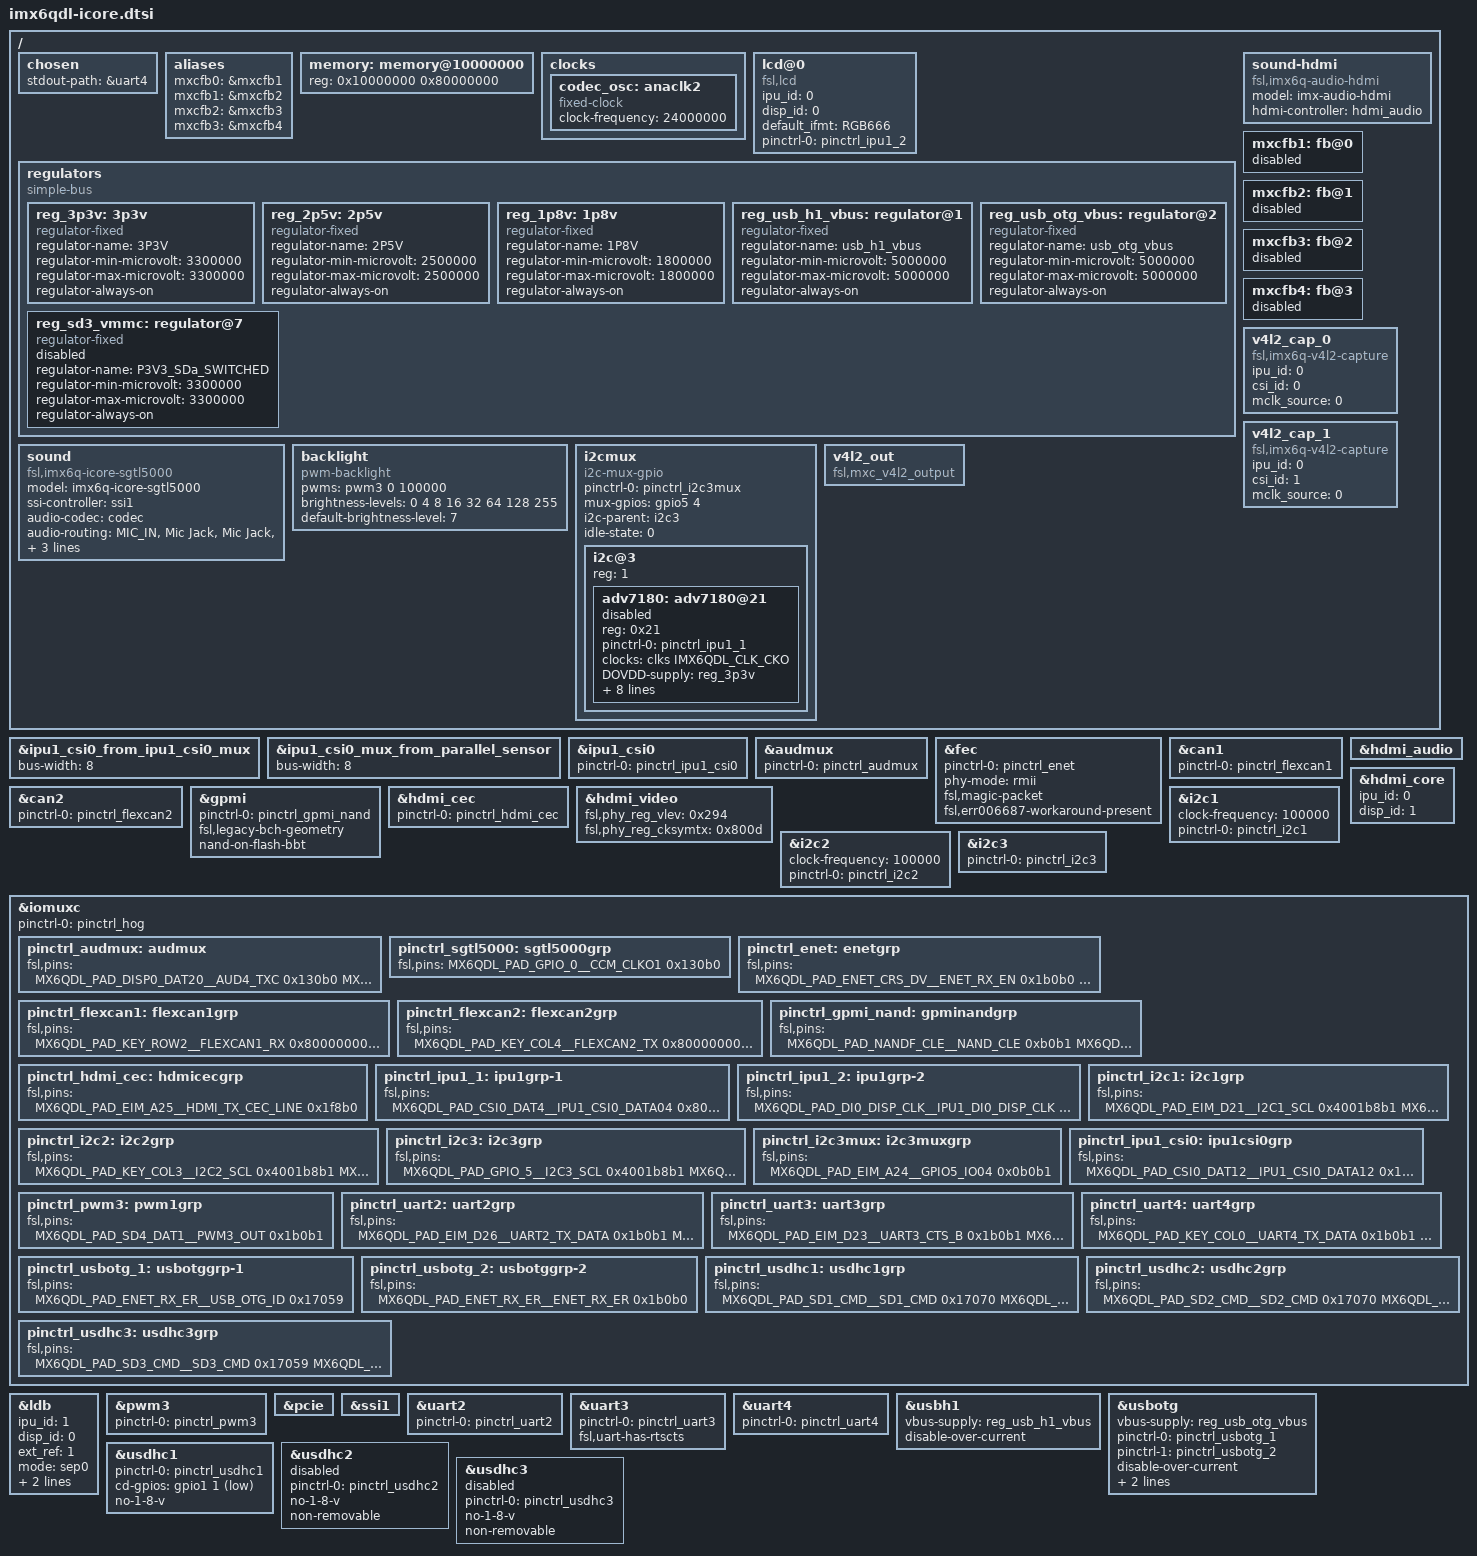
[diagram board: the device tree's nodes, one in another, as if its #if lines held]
// SPDX-License-Identifier: GPL-2.0+
//
// Copyright 2012 Freescale Semiconductor, Inc.
// Copyright 2011 Linaro Ltd.
// Based on imx6qdl-sabreauto.dtsi

#include <dt-bindings/gpio/gpio.h>
#include <dt-bindings/input/input.h>
#include "icore-imx6dl-pinfunc.h"
/ {
  
	chosen {
		stdout-path = &uart4;
	};

	aliases {
		mxcfb0 = &mxcfb1;
		mxcfb1 = &mxcfb2;
		mxcfb2 = &mxcfb3;
		mxcfb3 = &mxcfb4;
	};

	memory: memory@10000000 {
		reg = <0x10000000 0x80000000>;
	};

	clocks {
		codec_osc: anaclk2 {
			compatible = "fixed-clock";
			#clock-cells = <0>;
			clock-frequency = <24000000>;
		};
	};

	lcd@0 {
		compatible = "fsl,lcd";
		ipu_id = <0>;
		disp_id = <0>;
		default_ifmt = "RGB666";
		pinctrl-names = "default";
		pinctrl-0 = <&pinctrl_ipu1_2>;
		status = "okay";
	};

	regulators {
		compatible = "simple-bus";
		#address-cells = <1>;
		#size-cells = <0>;


		reg_3p3v: 3p3v {
			compatible = "regulator-fixed";
			regulator-name = "3P3V";
			regulator-min-microvolt = <3300000>;
			regulator-max-microvolt = <3300000>;
			regulator-always-on;
		};

		reg_2p5v: 2p5v {
			compatible = "regulator-fixed";
			regulator-name = "2P5V";
			regulator-min-microvolt = <2500000>;
			regulator-max-microvolt = <2500000>;
			regulator-always-on;
		};

		reg_1p8v: 1p8v {
			compatible = "regulator-fixed";
			regulator-name = "1P8V";
			regulator-min-microvolt = <1800000>;
			regulator-max-microvolt = <1800000>;
			regulator-always-on;
		};

		reg_usb_h1_vbus: regulator@1 {
			compatible = "regulator-fixed";
			regulator-name = "usb_h1_vbus";
			regulator-min-microvolt = <5000000>;
			regulator-max-microvolt = <5000000>;
			regulator-always-on;
		};

		reg_usb_otg_vbus: regulator@2 {
			compatible = "regulator-fixed";
			regulator-name = "usb_otg_vbus";
			regulator-min-microvolt = <5000000>;
			regulator-max-microvolt = <5000000>;
			regulator-always-on;
		};

		reg_sd3_vmmc: regulator@7 {
			compatible = "regulator-fixed";
			regulator-name = "P3V3_SDa_SWITCHED";
			regulator-min-microvolt = <3300000>;
			regulator-max-microvolt = <3300000>;
			regulator-always-on;
			status = "disabled";
		};

	};

	sound {
		compatible = "fsl,imx6q-icore-sgtl5000",
			     "fsl,imx-audio-sgtl5000";
		model = "imx6q-icore-sgtl5000";
		ssi-controller = <&ssi1>;
		audio-codec = <&codec>;
		audio-routing =
			"MIC_IN", "Mic Jack",
			"Mic Jack", "Mic Bias",
			"Headphone Jack", "HP_OUT";
		mux-int-port = <1>;
		mux-ext-port = <4>;
	};

	sound-hdmi {
		compatible = "fsl,imx6q-audio-hdmi",
			     "fsl,imx-audio-hdmi";
		model = "imx-audio-hdmi";
		hdmi-controller = <&hdmi_audio>;
	};

	mxcfb1: fb@0 {
		status = "disabled";
	};

	mxcfb2: fb@1 {
		status = "disabled";
	};

	mxcfb3: fb@2 {
		status = "disabled";
	};

	mxcfb4: fb@3 {
		status = "disabled";
	};



	backlight {
		compatible = "pwm-backlight";
		pwms = <&pwm3 0 100000>;
		brightness-levels = <0 4 8 16 32 64 128 255>;
		default-brightness-level = <7>;
		status = "okay";
	};

#ifdef TBT
	i2cmux { /* TBT */
		compatible = "i2c-mux-gpio";
		#address-cells = <1>;
		#size-cells = <0>;
		pinctrl-names = "default";
		pinctrl-0 = <&pinctrl_i2c3mux>;
		mux-gpios = <&gpio5 4 0>;
		i2c-parent = <&i2c3>;
		idle-state = <0>;

		i2c@3 {
			#address-cells = <1>;
			#size-cells = <0>;
			reg = <1>;

			adv7180: adv7180@21 {
				status = "disabled"
				compatible = "adv,adv7180";
				reg = <0x21>;
				pinctrl-names = "default";
				pinctrl-0 = <&pinctrl_ipu1_1>;
				clocks = <&clks IMX6QDL_CLK_CKO>;
				clock-names = "csi_mclk";
				DOVDD-supply = <&reg_3p3v>; /* 3.3v, enabled via 2.8 VGEN6 */
				AVDD-supply = <&reg_3p3v>;  /* 1.8v */
				DVDD-supply = <&reg_3p3v>;  /* 1.8v */
				PVDD-supply = <&reg_3p3v>;  /* 1.8v */
				pwn-gpios = <&max7310_b 2 0>;
				csi_id = <0>;
				mclk = <24000000>;
				mclk_source = <0>;
				cvbs = <1>;
			};

		};
	};
#endif
  
	v4l2_cap_0 {
		compatible = "fsl,imx6q-v4l2-capture";
		ipu_id = <0>;
		csi_id = <0>;
		mclk_source = <0>;
		status = "okay";
	};

	v4l2_cap_1 {
		compatible = "fsl,imx6q-v4l2-capture";
		ipu_id = <0>;
		csi_id = <1>;
		mclk_source = <0>;
		status = "okay";
	};

	v4l2_out {
		compatible = "fsl,mxc_v4l2_output";
		status = "okay";
	};
};

&ipu1_csi0_from_ipu1_csi0_mux {
	bus-width = <8>;
};

&ipu1_csi0_mux_from_parallel_sensor {
	/* Downstream driver doesn't use endpoints */
	/*
	remote-endpoint = <&adv7180_to_ipu1_csi0_mux>;
	 */
	bus-width = <8>;
};

&ipu1_csi0 {
	pinctrl-names = "default";
	pinctrl-0 = <&pinctrl_ipu1_csi0>;
};

&audmux {
	pinctrl-names = "default";
	pinctrl-0 = <&pinctrl_audmux>;
	status = "okay";
};

&fec {
	pinctrl-names = "default";
	pinctrl-0 = <&pinctrl_enet>;
	phy-mode = "rmii";
	fsl,magic-packet;
	fsl,err006687-workaround-present;
	status = "okay";
};

&can1 {
	pinctrl-names = "default";
	pinctrl-0 = <&pinctrl_flexcan1>;
	status = "okay"; 
};

&can2 {
	pinctrl-names = "default";
	pinctrl-0 = <&pinctrl_flexcan2>;
	status = "okay";
};

&gpmi {
	pinctrl-names = "default";
	pinctrl-0 = <&pinctrl_gpmi_nand>;
	status = "okay"; 
	fsl,legacy-bch-geometry;
	nand-on-flash-bbt;
};

&hdmi_audio {
	status = "okay";
};

&hdmi_cec {
	pinctrl-names = "default";
	pinctrl-0 = <&pinctrl_hdmi_cec>;
	status = "okay";
};

&hdmi_core {
	ipu_id = <0>;
	disp_id = <1>;
	status = "okay";
};

&hdmi_video {
	fsl,phy_reg_vlev = <0x294>;
	fsl,phy_reg_cksymtx = <0x800d>;
	status = "okay";
};

&i2c1 {
	status = "okay";
	clock-frequency = <100000>;
	pinctrl-names = "default";
	pinctrl-0 = <&pinctrl_i2c1>;

};

&i2c2 {
	clock-frequency = <100000>;
	pinctrl-names = "default";
	pinctrl-0 = <&pinctrl_i2c2>;
	status = "okay";
};

&i2c3 {
	pinctrl-names = "default";
	pinctrl-0 = <&pinctrl_i2c3>;
	status = "okay";
};

&iomuxc {
	pinctrl-names = "default";
	pinctrl-0 = <&pinctrl_hog>;

  pinctrl_audmux: audmux {
    fsl,pins = <
      MX6QDL_PAD_DISP0_DAT20__AUD4_TXC  0x130b0
      MX6QDL_PAD_DISP0_DAT21__AUD4_TXD 0x110b0
      MX6QDL_PAD_DISP0_DAT22__AUD4_TXFS  0x130b0
      MX6QDL_PAD_DISP0_DAT23__AUD4_RXD  0x130b0
      >;
  };

  /*pinctrl_hog: hoggrp {
    fsl,pins = <
      MX6QDL_PAD_SD3_CMD__GPIO7_IO02 0x1f059
    >;
  };*/
  
  pinctrl_sgtl5000: sgtl5000grp {
    fsl,pins = <
     MX6QDL_PAD_GPIO_0__CCM_CLKO1	0x130b0
     // MX6QDL_PAD_EIM_A25__GPIO5_IO02		0x1b0b0
    >;
  };

  pinctrl_enet: enetgrp {
    fsl,pins = <
      MX6QDL_PAD_ENET_CRS_DV__ENET_RX_EN 	0x1b0b0
      MX6QDL_PAD_ENET_TX_EN__ENET_TX_EN	0x1b0b0
      MX6QDL_PAD_ENET_RXD1__ENET_RX_DATA1	0x1b0b0
      MX6QDL_PAD_ENET_RXD0__ENET_RX_DATA0	0x1b0b0
      MX6QDL_PAD_ENET_TXD1__ENET_TX_DATA1	0x1b0b0
      MX6QDL_PAD_ENET_TXD0__ENET_TX_DATA0	0x1b0b0
            MX6QDL_PAD_ENET_MDC__ENET_MDC		0x1b0b0
      MX6QDL_PAD_ENET_MDIO__ENET_MDIO		0x1b0b0
      MX6QDL_PAD_ENET_REF_CLK__GPIO1_IO23	0x1b0b0
      MX6QDL_PAD_GPIO_17__GPIO7_IO12		0x1b0b0
      MX6QDL_PAD_EIM_BCLK__GPIO6_IO31		0x1b0b0 /* EDIMM 1.5 or 1.0 GPIO signal */
      MX6QDL_PAD_GPIO_16__ENET_REF_CLK_SION 0x4001b0a8
    >;
  };

  pinctrl_flexcan1: flexcan1grp {
    fsl,pins = <
      MX6QDL_PAD_KEY_ROW2__FLEXCAN1_RX 0x80000000
      MX6QDL_PAD_KEY_COL2__FLEXCAN1_TX 0x80000000
    >;
  };

  pinctrl_flexcan2: flexcan2grp {
    fsl,pins = <
      MX6QDL_PAD_KEY_COL4__FLEXCAN2_TX 0x80000000
      MX6QDL_PAD_KEY_ROW4__FLEXCAN2_RX 0x80000000
    >;
  };


  pinctrl_gpmi_nand: gpminandgrp {
    fsl,pins = <
      MX6QDL_PAD_NANDF_CLE__NAND_CLE		0xb0b1
      MX6QDL_PAD_NANDF_ALE__NAND_ALE		0xb0b1
      MX6QDL_PAD_NANDF_WP_B__NAND_WP_B	0xb0b1
      MX6QDL_PAD_NANDF_RB0__NAND_READY_B	0xb000
      MX6QDL_PAD_NANDF_CS0__NAND_CE0_B	0xb0b1
      MX6QDL_PAD_NANDF_CS1__NAND_CE1_B	0xb0b1
      MX6QDL_PAD_SD4_CMD__NAND_RE_B		0xb0b1
      MX6QDL_PAD_SD4_CLK__NAND_WE_B		0xb0b1
      MX6QDL_PAD_NANDF_D0__NAND_DATA00	0xb0b1
      MX6QDL_PAD_NANDF_D1__NAND_DATA01	0xb0b1
      MX6QDL_PAD_NANDF_D2__NAND_DATA02	0xb0b1
      MX6QDL_PAD_NANDF_D3__NAND_DATA03	0xb0b1
      MX6QDL_PAD_NANDF_D4__NAND_DATA04	0xb0b1
      MX6QDL_PAD_NANDF_D5__NAND_DATA05	0xb0b1
      MX6QDL_PAD_NANDF_D6__NAND_DATA06	0xb0b1
      MX6QDL_PAD_NANDF_D7__NAND_DATA07	0xb0b1
      MX6QDL_PAD_SD4_DAT0__NAND_DQS		0x00b1
    >;
  };

  pinctrl_hdmi_cec: hdmicecgrp {
    fsl,pins = <
      MX6QDL_PAD_EIM_A25__HDMI_TX_CEC_LINE	0x1f8b0
    >;
  };

  pinctrl_ipu1_1: ipu1grp-1 { /* parallel port 16-bit */
    fsl,pins = <
      MX6QDL_PAD_CSI0_DAT4__IPU1_CSI0_DATA04   0x80000000
      MX6QDL_PAD_CSI0_DAT5__IPU1_CSI0_DATA05   0x80000000
      MX6QDL_PAD_CSI0_DAT6__IPU1_CSI0_DATA06   0x80000000
      MX6QDL_PAD_CSI0_DAT7__IPU1_CSI0_DATA07   0x80000000
      MX6QDL_PAD_CSI0_DAT8__IPU1_CSI0_DATA08   0x80000000
      MX6QDL_PAD_CSI0_DAT9__IPU1_CSI0_DATA09   0x80000000
      MX6QDL_PAD_CSI0_DAT10__IPU1_CSI0_DATA10  0x80000000
      MX6QDL_PAD_CSI0_DAT11__IPU1_CSI0_DATA11  0x80000000
      MX6QDL_PAD_CSI0_DAT12__IPU1_CSI0_DATA12  0x80000000
      MX6QDL_PAD_CSI0_DAT13__IPU1_CSI0_DATA13  0x80000000
      MX6QDL_PAD_CSI0_DAT14__IPU1_CSI0_DATA14  0x80000000
      MX6QDL_PAD_CSI0_DAT15__IPU1_CSI0_DATA15  0x80000000
      MX6QDL_PAD_CSI0_DAT16__IPU1_CSI0_DATA16  0x80000000
      MX6QDL_PAD_CSI0_DAT17__IPU1_CSI0_DATA17  0x80000000
      MX6QDL_PAD_CSI0_DAT18__IPU1_CSI0_DATA18  0x80000000
      MX6QDL_PAD_CSI0_DAT19__IPU1_CSI0_DATA19  0x80000000
      MX6QDL_PAD_CSI0_PIXCLK__IPU1_CSI0_PIXCLK 0x80000000
      MX6QDL_PAD_CSI0_MCLK__IPU1_CSI0_HSYNC    0x80000000
      MX6QDL_PAD_CSI0_VSYNC__IPU1_CSI0_VSYNC   0x80000000
    >;
  };

  pinctrl_ipu1_2: ipu1grp-2 { 
    fsl,pins = <
      MX6QDL_PAD_DI0_DISP_CLK__IPU1_DI0_DISP_CLK 0x10
      MX6QDL_PAD_DI0_PIN15__IPU1_DI0_PIN15       0x10
      MX6QDL_PAD_DI0_PIN2__IPU1_DI0_PIN02        0x10
      MX6QDL_PAD_DI0_PIN3__IPU1_DI0_PIN03        0x10
      MX6QDL_PAD_DI0_PIN4__IPU1_DI0_PIN04        0x80000000
      MX6QDL_PAD_DISP0_DAT0__IPU1_DISP0_DATA00   0x10
      MX6QDL_PAD_DISP0_DAT1__IPU1_DISP0_DATA01   0x10
      MX6QDL_PAD_DISP0_DAT2__IPU1_DISP0_DATA02   0x10
      MX6QDL_PAD_DISP0_DAT3__IPU1_DISP0_DATA03   0x10
      MX6QDL_PAD_DISP0_DAT4__IPU1_DISP0_DATA04   0x10
      MX6QDL_PAD_DISP0_DAT5__IPU1_DISP0_DATA05   0x10
      MX6QDL_PAD_DISP0_DAT6__IPU1_DISP0_DATA06   0x10
      MX6QDL_PAD_DISP0_DAT7__IPU1_DISP0_DATA07   0x10
      MX6QDL_PAD_DISP0_DAT8__IPU1_DISP0_DATA08   0x10
      MX6QDL_PAD_DISP0_DAT9__IPU1_DISP0_DATA09   0x10
      MX6QDL_PAD_DISP0_DAT10__IPU1_DISP0_DATA10  0x10
      MX6QDL_PAD_DISP0_DAT11__IPU1_DISP0_DATA11  0x10
      MX6QDL_PAD_DISP0_DAT12__IPU1_DISP0_DATA12  0x10
      MX6QDL_PAD_DISP0_DAT13__IPU1_DISP0_DATA13  0x10
      MX6QDL_PAD_DISP0_DAT14__IPU1_DISP0_DATA14  0x10
      MX6QDL_PAD_DISP0_DAT15__IPU1_DISP0_DATA15  0x10
      MX6QDL_PAD_DISP0_DAT16__IPU1_DISP0_DATA16  0x10
      MX6QDL_PAD_DISP0_DAT17__IPU1_DISP0_DATA17  0x10
    >;
  };

  pinctrl_i2c1: i2c1grp {
    fsl,pins = <
      MX6QDL_PAD_EIM_D21__I2C1_SCL 0x4001b8b1
      MX6QDL_PAD_EIM_D28__I2C1_SDA 0x4001b8b1
    >;
  };

  pinctrl_i2c2: i2c2grp {
    fsl,pins = <
      MX6QDL_PAD_KEY_COL3__I2C2_SCL 0x4001b8b1
      MX6QDL_PAD_KEY_ROW3__I2C2_SDA 0x4001b8b1
    >;
  };

  pinctrl_i2c3: i2c3grp {
    fsl,pins = <
      MX6QDL_PAD_GPIO_5__I2C3_SCL  0x4001b8b1
      MX6QDL_PAD_EIM_D18__I2C3_SDA 0x4001b8b1
     // MX6QDL_PAD_GPIO_0__CCM_CLKO1	0x130b0
    >;
  };

  pinctrl_i2c3mux: i2c3muxgrp {
    fsl,pins = <
      MX6QDL_PAD_EIM_A24__GPIO5_IO04 0x0b0b1
    >;
  };

  pinctrl_ipu1_csi0: ipu1csi0grp {
    fsl,pins = <
      MX6QDL_PAD_CSI0_DAT12__IPU1_CSI0_DATA12  0x1b0b0
      MX6QDL_PAD_CSI0_DAT13__IPU1_CSI0_DATA13  0x1b0b0
      MX6QDL_PAD_CSI0_DAT14__IPU1_CSI0_DATA14  0x1b0b0
      MX6QDL_PAD_CSI0_DAT15__IPU1_CSI0_DATA15  0x1b0b0
      MX6QDL_PAD_CSI0_DAT16__IPU1_CSI0_DATA16  0x1b0b0
      MX6QDL_PAD_CSI0_DAT17__IPU1_CSI0_DATA17  0x1b0b0
      MX6QDL_PAD_CSI0_DAT18__IPU1_CSI0_DATA18  0x1b0b0
      MX6QDL_PAD_CSI0_DAT19__IPU1_CSI0_DATA19  0x1b0b0
      MX6QDL_PAD_CSI0_PIXCLK__IPU1_CSI0_PIXCLK 0x1b0b0
      MX6QDL_PAD_CSI0_MCLK__IPU1_CSI0_HSYNC    0x1b0b0
      MX6QDL_PAD_CSI0_VSYNC__IPU1_CSI0_VSYNC   0x1b0b0
    >;
  };

  pinctrl_pwm3: pwm1grp {
    fsl,pins = <
      MX6QDL_PAD_SD4_DAT1__PWM3_OUT		0x1b0b1
    >;
  };



  pinctrl_uart2: uart2grp {
    fsl,pins = <
      MX6QDL_PAD_EIM_D26__UART2_TX_DATA 0x1b0b1
      MX6QDL_PAD_EIM_D27__UART2_RX_DATA 0x1b0b1
    >;
  };

  pinctrl_uart3: uart3grp {
    fsl,pins = <
      MX6QDL_PAD_EIM_D23__UART3_CTS_B   0x1b0b1
      MX6QDL_PAD_EIM_D24__UART3_TX_DATA 0x1b0b1
      MX6QDL_PAD_EIM_D25__UART3_RX_DATA 0x1b0b1
    >;
  };

  pinctrl_uart4: uart4grp {
    fsl,pins = <
      MX6QDL_PAD_KEY_COL0__UART4_TX_DATA	0x1b0b1
      MX6QDL_PAD_KEY_ROW0__UART4_RX_DATA	0x1b0b1
    >;
  };

  pinctrl_usbotg_1: usbotggrp-1 {
    fsl,pins = <
      MX6QDL_PAD_ENET_RX_ER__USB_OTG_ID 0x17059
    >;
  };

  pinctrl_usbotg_2: usbotggrp-2 {
    fsl,pins = <
      MX6QDL_PAD_ENET_RX_ER__ENET_RX_ER	0x1b0b0
    >;
  };

  pinctrl_usdhc1: usdhc1grp {
    fsl,pins = <
      MX6QDL_PAD_SD1_CMD__SD1_CMD    0x17070
      MX6QDL_PAD_SD1_CLK__SD1_CLK    0x10070
      MX6QDL_PAD_SD1_DAT0__SD1_DATA0 0x17070
      MX6QDL_PAD_SD1_DAT1__SD1_DATA1 0x17070
      MX6QDL_PAD_SD1_DAT2__SD1_DATA2 0x17070
      MX6QDL_PAD_SD1_DAT3__SD1_DATA3 0x17070
    >;
  };

  pinctrl_usdhc2: usdhc2grp {
    fsl,pins = <
      MX6QDL_PAD_SD2_CMD__SD2_CMD    0x17070
      MX6QDL_PAD_SD2_CLK__SD2_CLK    0x10070
      MX6QDL_PAD_SD2_DAT0__SD2_DATA0 0x17070
      MX6QDL_PAD_SD2_DAT1__SD2_DATA1 0x17070
      MX6QDL_PAD_SD2_DAT2__SD2_DATA2 0x17070
      MX6QDL_PAD_SD2_DAT3__SD2_DATA3 0x17070
    >;
  };

  pinctrl_usdhc3: usdhc3grp {
    fsl,pins = <
      MX6QDL_PAD_SD3_CMD__SD3_CMD    0x17059
      MX6QDL_PAD_SD3_CLK__SD3_CLK    0x10059
      MX6QDL_PAD_SD3_DAT0__SD3_DATA0 0x17059
      MX6QDL_PAD_SD3_DAT1__SD3_DATA1 0x17059
      MX6QDL_PAD_SD3_DAT2__SD3_DATA2 0x17059
      MX6QDL_PAD_SD3_DAT3__SD3_DATA3 0x17059
      MX6QDL_PAD_SD3_DAT4__SD3_DATA4 0x17059
      MX6QDL_PAD_SD3_DAT5__SD3_DATA5 0x17059
      MX6QDL_PAD_SD3_DAT6__SD3_DATA6 0x17059
      MX6QDL_PAD_SD3_DAT7__SD3_DATA7 0x17059
    >;
  };
};

&ldb {
	ipu_id = <1>;
	disp_id = <0>;
	ext_ref = <1>;
	mode = "sep0";
	sec_ipu_id = <1>;
	sec_disp_id = <1>;
	status = "okay";
};


&pwm3 {
	pinctrl-names = "default";
	pinctrl-0 = <&pinctrl_pwm3>;
	status = "okay";
};

&pcie {
	status = "okay";
};

&ssi1 {
  //fsl,mode = "i2s-slave";
	status = "okay";
};

&uart2 {
	pinctrl-names = "default";
	pinctrl-0 = <&pinctrl_uart2>;
	status = "okay";
};

&uart3 {
	pinctrl-names = "default";
	pinctrl-0 = <&pinctrl_uart3>;
   	fsl,uart-has-rtscts;
	status = "okay";
};

&uart4 {
	pinctrl-names = "default";
	pinctrl-0 = <&pinctrl_uart4>;
	status = "okay";
};

&usbh1 {
	vbus-supply = <&reg_usb_h1_vbus>;
	disable-over-current;
	status = "okay";
};

&usbotg {
	vbus-supply = <&reg_usb_otg_vbus>;
	pinctrl-names = "default", "rev_c";
	pinctrl-0 = <&pinctrl_usbotg_1>;
	pinctrl-1 = <&pinctrl_usbotg_2>;
	disable-over-current;
	ver-gpios = <&gpio7 2 0>;
	dr_mode="otg";
	status = "okay";
};

&usdhc1 {
	pinctrl-names = "default";
	pinctrl-0 = <&pinctrl_usdhc1>;
	cd-gpios = <&gpio1 1 GPIO_ACTIVE_LOW>;
	no-1-8-v;
	status = "okay";
};

&usdhc2 {
	pinctrl-names = "default";
	pinctrl-0 = <&pinctrl_usdhc2>;
	no-1-8-v;
	non-removable;
	status = "disabled";
};

&usdhc3 {
	pinctrl-names = "default";
	pinctrl-0 = <&pinctrl_usdhc3>;
	no-1-8-v;
	non-removable;
	status = "disabled";
};


